# STM32G491 register map
File version: 1.9
CPU: CM4 r0p1, little endian, MPU, FPU, 4 interrupt priority bits
Registers are 32-bit, read-write, reset 0x0 unless marked. A register's access mark holds for its fields unless they carry their own. Offsets are from the block's base; [hi:lo] are bit positions; {n}, {i} and the like mark numbered series.

## DMAMUX
Base 0x40020800
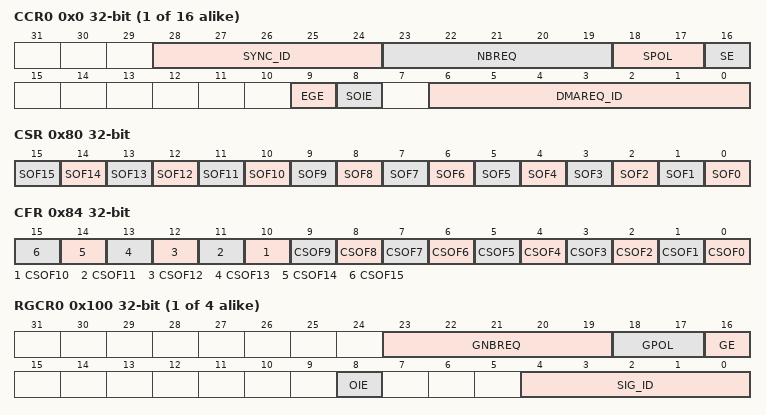
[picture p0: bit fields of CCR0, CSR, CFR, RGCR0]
{0x0+4i} CCR{i} (i=0..15) — DMA Multiplexer Channel {i} Control register
  [28:24] SYNC_ID — Synchronization input selected
  [23:19] NBREQ — Number of DMA requests to forward Defines the number of DMA requests forwarded before output event is generated. In synchronous mode, it also defines the number of DMA requests to forward after a synchronization event, then stop forwarding. The actual number of DMA requests forwarded is NBREQ+1. Note: This field can only be written when both SE and EGE bits are reset.
  [18:17] SPOL — Synchronization event type selector Defines the synchronization event on the selected synchronization input:
    0=NoEdge (No event, i.e. no synchronization nor detection); 1=RisingEdge; 2=FallingEdge; 3=BothEdges (Rising and falling edges)
  [16] SE — Synchronous operating mode enable/disable
    0=Disabled (Synchronization disabled); 1=Enabled (Synchronization enabled)
  [9] EGE — Event generation enable/disable
    0=Disabled (Event generation disabled); 1=Enabled (Event generation enabled)
  [8] SOIE — Interrupt enable at synchronization event overrun
    0=Disabled (Synchronization overrun interrupt disabled); 1=Enabled (Synchronization overrun interrupt enabled)
  [6:0] DMAREQ_ID — Input DMA request line selected
0x80 CSR ro — DMAMUX request line multiplexer interrupt channel status register
  [n] SOF{n} (n=0..15) — Synchronization Overrun Flag {n}
    0=NoSyncEvent (No synchronization event occured on a DMA request line multiplexer channel x, while the DMA request counter value is lower than NBREQ); 1=SyncEvent (Synchronization event occured on a DMA request line multiplexer channel x, while the DMA request counter value is lower than NBREQ)
0x84 CFR wo — DMAMUX request line multiplexer interrupt clear flag register
  [n] CSOF{n} (n=0..15) write-1-clears — Synchronization Clear Overrun Flag {n}
    1=Clear synchronization flag
{0x100+4i} RGCR{i} (i=0..3) — DMAMux - DMA request generator channel x control register
  [23:19] GNBREQ — Number of DMA requests to generate Defines the number of DMA requests generated after a trigger event, then stop generating. The actual number of generated DMA requests is GNBREQ+1. Note: This field can only be written when GE bit is reset.
  [18:17] GPOL — DMA request generator trigger event type selection Defines the trigger event on the selected DMA request trigger input
    0=NoEdge (No event, i.e. no detection nor generation); 1=RisingEdge; 2=FallingEdge; 3=BothEdges (Rising and falling edges)
  [16] GE — DMA request generator channel enable/disable
    0=Disabled (DMA request generation disabled); 1=Enabled (DMA request enabled)
  [8] OIE — Interrupt enable at trigger event overrun
    0=Disabled (Trigger overrun interrupt disabled); 1=Enabled (Trigger overrun interrupt enabled)
  [4:0] SIG_ID — DMA request trigger input selected
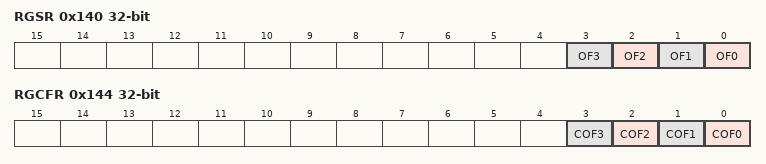
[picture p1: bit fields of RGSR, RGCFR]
0x140 RGSR ro — DMAMux - DMA request generator status register
  [n] OF{n} (n=0..3) — Generator Overrun Flag {n}
    0=NoTrigger (No new trigger event occured on DMA request generator channel x, before the request counter underrun); 1=Trigger (New trigger event occured on DMA request generator channel x, before the request counter underrun)
0x144 RGCFR wo — DMAMux - DMA request generator clear flag register
  [n] COF{n} (n=0..3) write-1-clears — Generator Clear Overrun Flag {n}
    1=Clear overrun flag

## SYSCFG — System configuration controller
Base 0x40010000
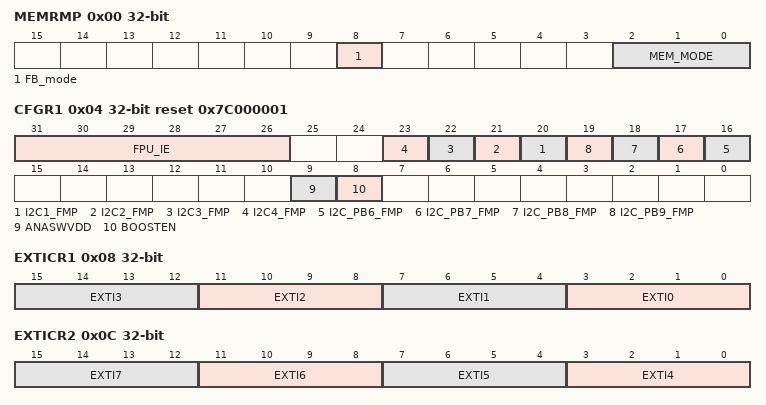
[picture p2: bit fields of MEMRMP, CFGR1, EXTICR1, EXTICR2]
0x00 MEMRMP — Remap Memory register
  [8] FB_mode — User Flash Bank mode
  [2:0] MEM_MODE — Memory mapping selection
0x04 CFGR1 reset 0x7C000001 — peripheral mode configuration register
  [31:26] FPU_IE — FPU Interrupts Enable
  [n+19] I2C{n}_FMP (n=1..4) — I2C1 FM+ drive capability enable
  [n+10] I2C_PB{n}_FMP (n=6..9) — FM+ drive capability on PB6
  [9] ANASWVDD — GPIO analog switch control voltage selection
  [8] BOOSTEN
0x08 EXTICR1 — external interrupt configuration register 1
  [4n+3:4n] EXTI{n} (n=0..3) — EXTI x configuration (x = 0 to 3)
0x0C EXTICR2 — external interrupt configuration register 2
  [4n-13:4n-16] EXTI{n} (n=4..7) — EXTI x configuration (x = 4 to 7)
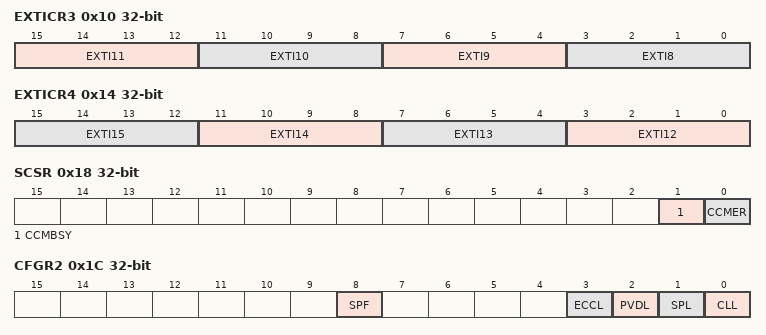
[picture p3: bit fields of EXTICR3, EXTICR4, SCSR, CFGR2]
0x10 EXTICR3 — external interrupt configuration register 3
  [15:12] EXTI11 — EXTI x configuration (x = 8 to 11)
  [11:8] EXTI10
  [7:4] EXTI9 — EXTI x configuration (x = 8 to 11)
  [3:0] EXTI8 — EXTI x configuration (x = 8 to 11)
0x14 EXTICR4 — external interrupt configuration register 4
  [4n-45:4n-48] EXTI{n} (n=12..15) — EXTI x configuration (x = 12 to 15)
0x18 SCSR access per field — CCM SRAM control and status register
  [1] CCMBSY ro — CCM SRAM busy by erase operation
  [0] CCMER rw — CCM SRAM Erase
0x1C CFGR2 — configuration register 2
  [8] SPF — SRAM Parity Flag
  [3] ECCL — ECC Lock
  [2] PVDL — PVD Lock
  [1] SPL — SRAM Parity Lock
  [0] CLL — Core Lockup Lock
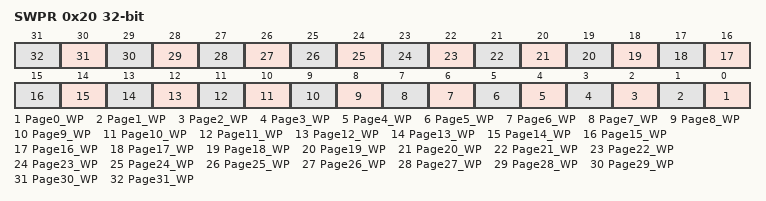
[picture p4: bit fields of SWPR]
0x20 SWPR — SRAM Write protection register 1
  [n] Page{n}_WP (n=0..31) — Write protection
0x24 SKR wo — SRAM2 Key Register
  [7:0] KEY — SRAM2 Key for software erase
